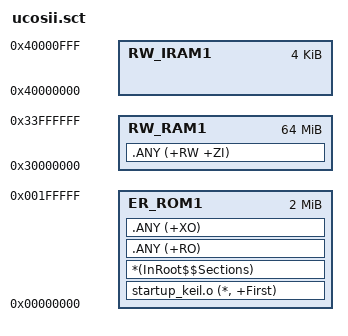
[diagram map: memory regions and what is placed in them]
LR_ROM1 0x00000000 0x00200000  {
  ER_ROM1 0x00000000 0x00200000  {
   startup_keil.o (*, +First)    ; 修复: *.o (RESET, +First) → startup_keil.o (*, +First)
   *(InRoot$$Sections)
   .ANY (+RO)
   .ANY (+XO)
  }
  RW_RAM1 0x30000000 0x04000000  {  ; 保持原设计: SDRAM 主数据区
   .ANY (+RW +ZI)
  }
  RW_IRAM1 0x40000000 0x00001000  {  ; 保持原设计: 内部 SRAM（可选）
  }
}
